# HC32F4A8 register map
File version: 1.0
CPU: CM4 r0p1, little endian, MPU, FPU, 4 interrupt priority bits
Registers are 32-bit, read-write, reset 0x0 unless marked. A register's access mark holds for its fields unless they carry their own. Offsets are from the block's base; [hi:lo] are bit positions; {n}, {i} and the like mark numbered series.

## I2C1 — desc I2C
Base 0x4004E000
Same registers: I2C2 0x4004E400, I2C3 0x4004E800, I2C4 0x4004EC00, I2C5 0x4004F000, I2C6 0x4004F800
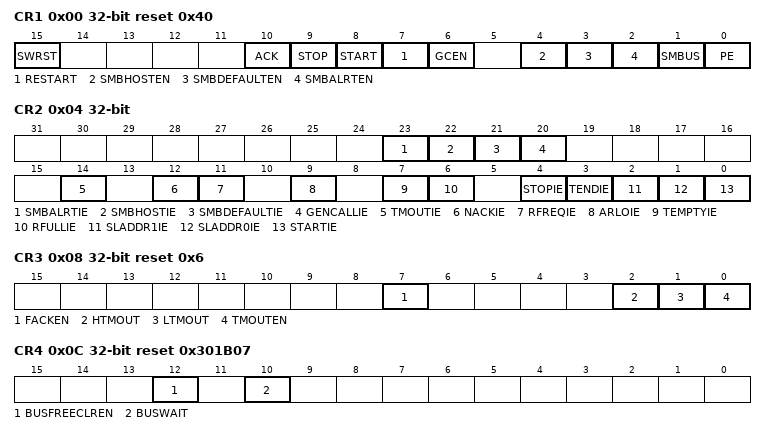
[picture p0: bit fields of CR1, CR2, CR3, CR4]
0x00 CR1 reset 0x40
  [15] SWRST, [10] ACK, [9] STOP, [8] START, [7] RESTART, [6] GCEN, [4] SMBHOSTEN, [3] SMBDEFAULTEN, [2] SMBALRTEN, [1] SMBUS, [0] PE
0x04 CR2
  [23] SMBALRTIE, [22] SMBHOSTIE, [21] SMBDEFAULTIE, [20] GENCALLIE, [14] TMOUTIE, [12] NACKIE, [11] RFREQIE, [9] ARLOIE, [7] TEMPTYIE, [6] RFULLIE, [4] STOPIE, [3] TENDIE, [2] SLADDR1IE, [1] SLADDR0IE, [0] STARTIE
0x08 CR3 reset 0x6
  [7] FACKEN, [2] HTMOUT, [1] LTMOUT, [0] TMOUTEN
0x0C CR4 reset 0x301B07
  [12] BUSFREECLREN, [10] BUSWAIT
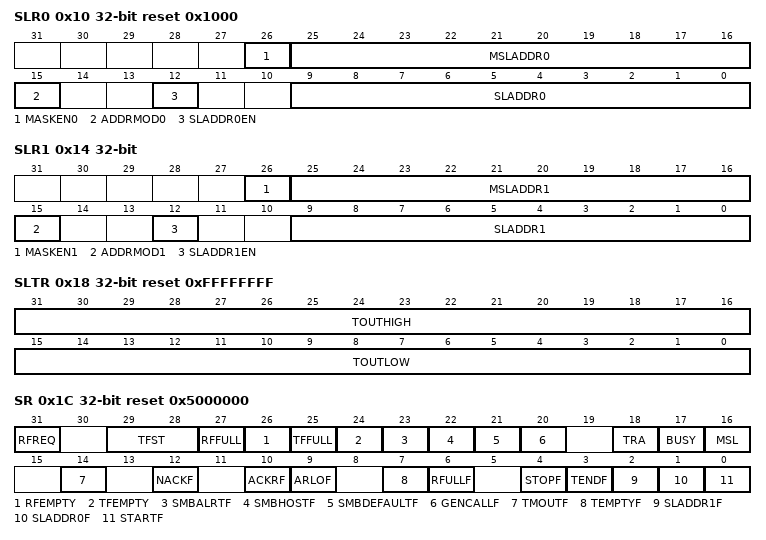
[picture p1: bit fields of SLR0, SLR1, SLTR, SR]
0x10 SLR0 reset 0x1000
  [26] MASKEN0, [25:16] MSLADDR0, [15] ADDRMOD0, [12] SLADDR0EN, [9:0] SLADDR0
0x14 SLR1
  [26] MASKEN1, [25:16] MSLADDR1, [15] ADDRMOD1, [12] SLADDR1EN, [9:0] SLADDR1
0x18 SLTR reset 0xFFFFFFFF
  [31:16] TOUTHIGH, [15:0] TOUTLOW
0x1C SR reset 0x5000000
  [31] RFREQ ro, [29:28] TFST ro, [27] RFFULL ro, [26] RFEMPTY ro, [25] TFFULL, [24] TFEMPTY ro, [23] SMBALRTF ro, [22] SMBHOSTF ro, [21] SMBDEFAULTF ro, [20] GENCALLF ro, [18] TRA, [17] BUSY ro, [16] MSL, [14] TMOUTF ro, [12] NACKF ro, [10] ACKRF ro, [9] ARLOF ro, [7] TEMPTYF ro, [6] RFULLF ro, [4] STOPF ro, [3] TENDF ro, [2] SLADDR1F ro, [1] SLADDR0F ro, [0] STARTF ro
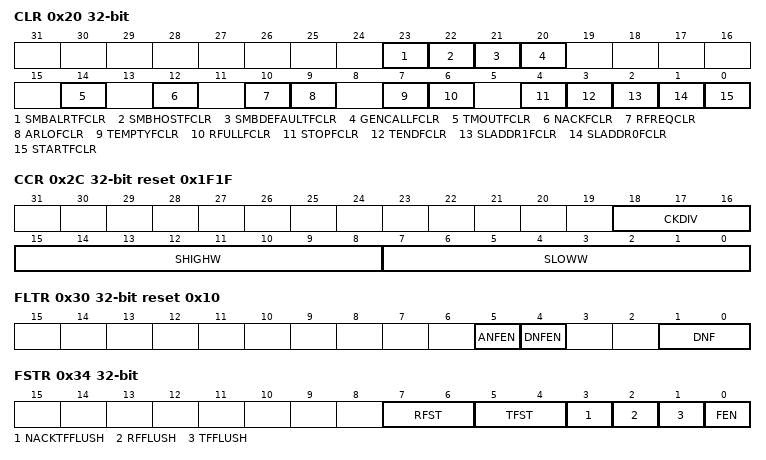
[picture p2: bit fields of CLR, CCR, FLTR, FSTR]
0x20 CLR wo
  [23] SMBALRTFCLR, [22] SMBHOSTFCLR, [21] SMBDEFAULTFCLR, [20] GENCALLFCLR, [14] TMOUTFCLR, [12] NACKFCLR, [10] RFREQCLR, [9] ARLOFCLR, [7] TEMPTYFCLR, [6] RFULLFCLR, [4] STOPFCLR, [3] TENDFCLR, [2] SLADDR1FCLR, [1] SLADDR0FCLR, [0] STARTFCLR
0x24 DTR 8-bit reset 0xFF
0x28 DRR 8-bit ro
0x2C CCR reset 0x1F1F
  [18:16] CKDIV, [15:8] SHIGHW, [7:0] SLOWW
0x30 FLTR reset 0x10
  [5] ANFEN, [4] DNFEN, [1:0] DNF
0x34 FSTR
  [7:6] RFST, [5:4] TFST, [3] NACKTFFLUSH, [2] RFFLUSH, [1] TFFLUSH, [0] FEN
0x38 SLVADDR
  [9:0] SLVADRR

## I2S1 — desc I2S
Base 0x4001E000
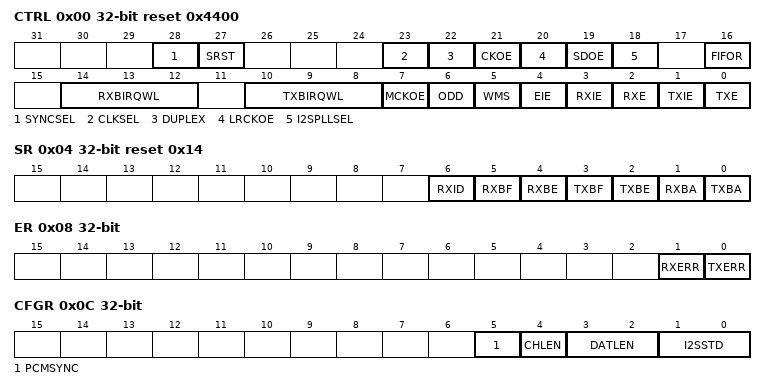
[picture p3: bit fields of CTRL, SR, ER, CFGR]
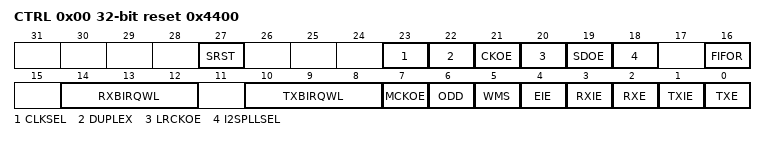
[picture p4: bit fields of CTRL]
0x00 CTRL reset 0x4400
  [28] SYNCSEL, [27] SRST, [23] CLKSEL, [22] DUPLEX, [21] CKOE, [20] LRCKOE, [19] SDOE, [18] I2SPLLSEL, [16] FIFOR, [14:12] RXBIRQWL, [10:8] TXBIRQWL, [7] MCKOE, [6] ODD, [5] WMS, [4] EIE, [3] RXIE, [2] RXE, [1] TXIE, [0] TXE
0x04 SR ro reset 0x14
  [6] RXID, [5] RXBF, [4] RXBE, [3] TXBF, [2] TXBE, [1] RXBA, [0] TXBA
0x08 ER
  [1] RXERR, [0] TXERR
0x0C CFGR
  [5] PCMSYNC, [4] CHLEN, [3:2] DATLEN, [1:0] I2SSTD
0x10 TXBUF wo
0x14 RXBUF ro
0x18 PR reset 0x2
  [7:0] I2SDIV

## I2S2 — desc I2S
Base 0x4001E400
Same registers: I2S3 0x40022000, I2S4 0x40022400
Registers as I2S1; these are added or differ:
0x00 CTRL reset 0x4400
  [27] SRST, [23] CLKSEL, [22] DUPLEX, [21] CKOE, [20] LRCKOE, [19] SDOE, [18] I2SPLLSEL, [16] FIFOR, [14:12] RXBIRQWL, [10:8] TXBIRQWL, [7] MCKOE, [6] ODD, [5] WMS, [4] EIE, [3] RXIE, [2] RXE, [1] TXIE, [0] TXE

## ICG
Base 0x00000400
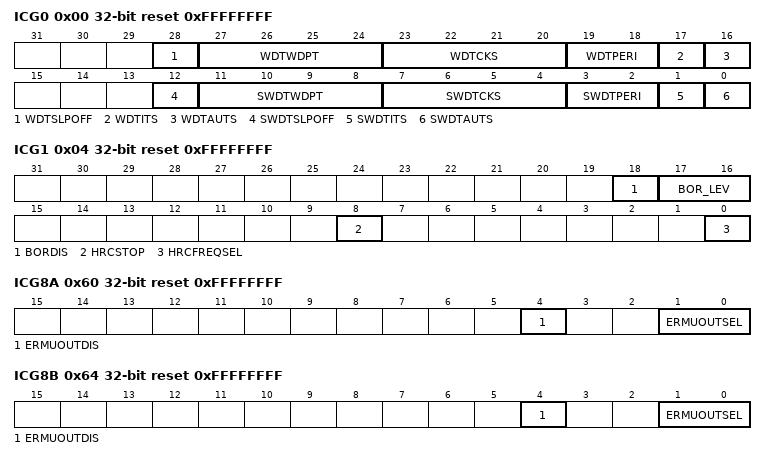
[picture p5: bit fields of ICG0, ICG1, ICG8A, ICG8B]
0x00 ICG0 ro reset 0xFFFFFFFF
  [28] WDTSLPOFF, [27:24] WDTWDPT, [23:20] WDTCKS, [19:18] WDTPERI, [17] WDTITS, [16] WDTAUTS, [12] SWDTSLPOFF, [11:8] SWDTWDPT, [7:4] SWDTCKS, [3:2] SWDTPERI, [1] SWDTITS, [0] SWDTAUTS
0x04 ICG1 ro reset 0xFFFFFFFF
  [18] BORDIS, [17:16] BOR_LEV, [8] HRCSTOP, [0] HRCFREQSEL
0x0C ICG3 ro reset 0xFFFFFFFF
  [15:0] DBUSPRT
0x60 ICG8A ro reset 0xFFFFFFFF
  [4] ERMUOUTDIS, [1:0] ERMUOUTSEL
0x64 ICG8B ro reset 0xFFFFFFFF
  [4] ERMUOUTDIS, [1:0] ERMUOUTSEL
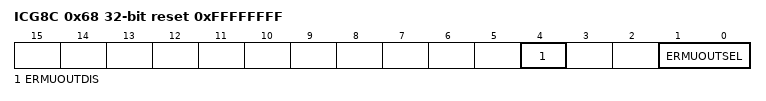
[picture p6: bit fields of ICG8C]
0x68 ICG8C ro reset 0xFFFFFFFF
  [4] ERMUOUTDIS, [1:0] ERMUOUTSEL

## INTC
Base 0x40051000
0x00 NOCCR
  [13:12] NOCSEL
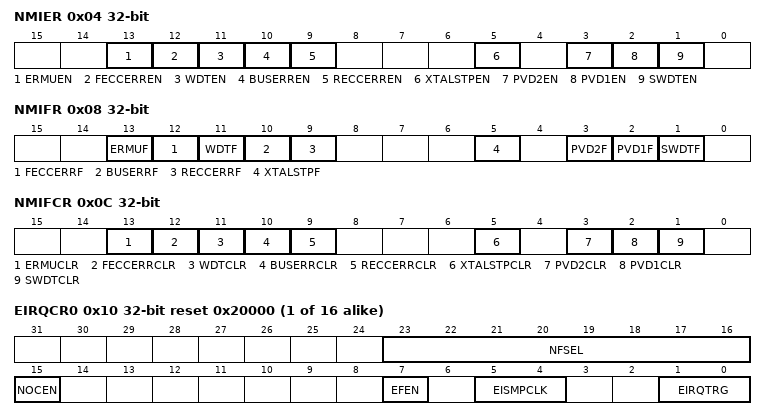
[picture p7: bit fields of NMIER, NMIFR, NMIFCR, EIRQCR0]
0x04 NMIER
  [13] ERMUEN, [12] FECCERREN, [11] WDTEN, [10] BUSERREN, [9] RECCERREN, [5] XTALSTPEN, [3] PVD2EN, [2] PVD1EN, [1] SWDTEN
0x08 NMIFR
  [13] ERMUF, [12] FECCERRF, [11] WDTF, [10] BUSERRF, [9] RECCERRF, [5] XTALSTPF, [3] PVD2F, [2] PVD1F, [1] SWDTF
0x0C NMIFCR
  [13] ERMUCLR, [12] FECCERRCLR, [11] WDTCLR, [10] BUSERRCLR, [9] RECCERRCLR, [5] XTALSTPCLR, [3] PVD2CLR, [2] PVD1CLR, [1] SWDTCLR
{0x10+4i} EIRQCR{i} reset 0x20000 (i=0..15)
  [23:16] NFSEL, [15] NOCEN, [7] EFEN, [5:4] EISMPCLK, [1:0] EIRQTRG
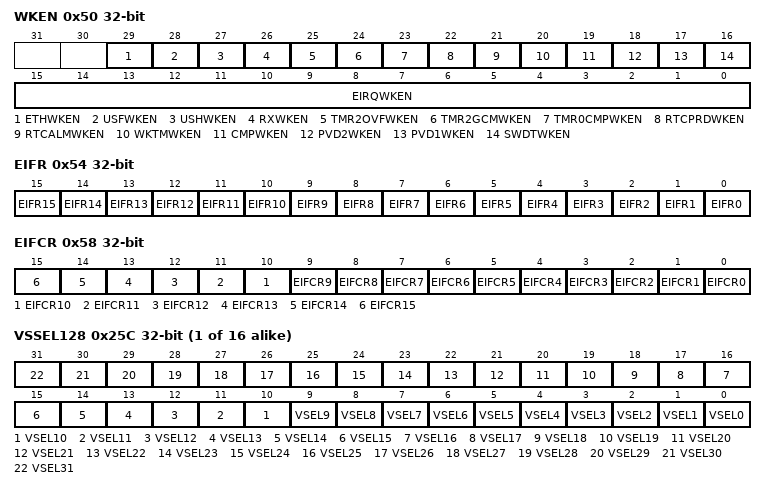
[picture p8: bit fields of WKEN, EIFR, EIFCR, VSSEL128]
0x50 WKEN
  [29] ETHWKEN, [28] USFWKEN, [27] USHWKEN, [26] RXWKEN, [25] TMR2OVFWKEN, [24] TMR2GCMWKEN, [23] TMR0CMPWKEN, [22] RTCPRDWKEN, [21] RTCALMWKEN, [20] WKTMWKEN, [19] CMPWKEN, [18] PVD2WKEN, [17] PVD1WKEN, [16] SWDTWKEN, [15:0] EIRQWKEN
0x54 EIFR
  [n] EIFR{n} (n=0..15)
0x58 EIFCR
  [n] EIFCR{n} (n=0..15)
{0x5C+4i} INTSEL{i} reset 0x1FF (i=0..127)
  [8:0] INTSEL
{0x5C+4i} VSSEL{i} (i=128..143)
  [n] VSEL{n} (n=0..31)
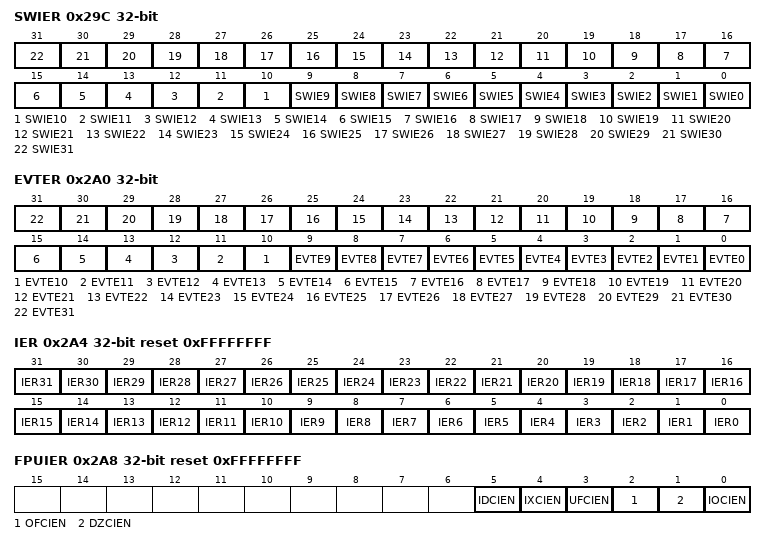
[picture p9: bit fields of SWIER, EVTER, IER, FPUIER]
0x29C SWIER
  [n] SWIE{n} (n=0..31)
0x2A0 EVTER
  [n] EVTE{n} (n=0..31)
0x2A4 IER reset 0xFFFFFFFF
  [n] IER{n} (n=0..31)
0x2A8 FPUIER reset 0xFFFFFFFF
  [5] IDCIEN, [4] IXCIEN, [3] UFCIEN, [2] OFCIEN, [1] DZCIEN, [0] IOCIEN
